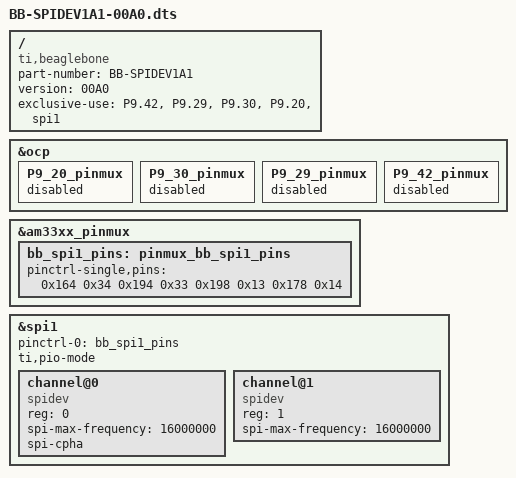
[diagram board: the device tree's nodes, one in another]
/*
 * Copyright (C) 2013 CircuitCo
 *
 * Virtual cape for SPI1 (ALT #1) on connector pins
 *
 * This program is free software; you can redistribute it and/or modify
 * it under the terms of the GNU General Public License version 2 as
 * published by the Free Software Foundation.
 */

/dts-v1/;
/plugin/;

#include <dt-bindings/board/am335x-bbw-bbb-base.h>
#include <dt-bindings/pinctrl/am33xx.h>

/ {
	compatible = "ti,beaglebone", "ti,beaglebone-black", "ti,beaglebone-green";

	/* identification */
	part-number = "BB-SPIDEV1A1";
	version = "00A0";

	/* state the resources this cape uses */
	exclusive-use =
		/* the pin header uses */
		"P9.42",	/* spi1_sclk */
		"P9.29",	/* spi1_d0 */
		"P9.30",	/* spi1_d1 */
		"P9.20",	/* spi1_cs0 */
		/* the hardware ip uses */
		"spi1";

	/*
	 * Free up the pins used by the cape from the pinmux helpers.
	 */
	fragment@0 {
		target = <&ocp>;
		__overlay__ {
			P9_20_pinmux { status = "disabled"; };	/* spi1_cs0 */
			P9_30_pinmux { status = "disabled"; };	/* spi1_d1 */
			P9_29_pinmux { status = "disabled"; };	/* spi1_d0 */
			P9_42_pinmux { status = "disabled"; };	/* spi1_sclk */
		};
	};

	fragment@1 {
		target = <&am33xx_pinmux>;
		__overlay__ {
			/* default state has all gpios released and mode set to uart1 */
			bb_spi1_pins: pinmux_bb_spi1_pins {
				pinctrl-single,pins = <
					0x164 0x34	/* eCAP0_in_PWM0_out.spi1_sclk, INPUT_PULLUP | MODE4 */
							/* NOTE: P9.42 is connected to two pads */
					// 0x1A0 0x27	/* set the other pad to gpio input */
					0x194 0x33	/* mcasp0_fsx.spi1_d0, INPUT_PULLUP | MODE3 */
					0x198 0x13	/* mcasp0_axr0.spi1_d1, OUTPUT_PULLUP | MODE3 */
					0x178 0x14	/* uart1_ctsn.spi1_cs0, OUTPUT_PULLUP | MODE4 */
				>;
			};
		};
	};

	fragment@2 {
		target = <&spi1>;
		__overlay__ {
			#address-cells = <1>;
			#size-cells = <0>;

			status = "okay";
			pinctrl-names = "default";
			pinctrl-0 = <&bb_spi1_pins>;
			ti,pio-mode; /* disable dma when used as an overlay, dma gets stuck at 160 bits... */

			channel@0 {
				#address-cells = <1>;
				#size-cells = <0>;

				compatible = "spidev";

				reg = <0>;
				spi-max-frequency = <16000000>;
				spi-cpha;
			};

			channel@1 {
				#address-cells = <1>;
				#size-cells = <0>;

				compatible = "spidev";

				reg = <1>;
				spi-max-frequency = <16000000>;
			};
		};
	};
};
